# QEMU_RISCV_VIRT register map
Vendor: qemu.org; Series: RISC-V; File version: 0.1
QEMU RISC-V Virt Machine Platform
CPU: riscv r0p0, little endian, no MPU, no FPU, 0 interrupt priority bits
Registers are 32-bit, read-write, reset 0x0 unless marked. A register's access mark holds for its fields unless they carry their own. Offsets are from the block's base; lines under a group give offsets from that group; [hi:lo] are bit positions; {n}, {i} and the like mark numbered series; 'fields as' and 'values as' point back to an identical list; <NAME> marks a mode.

## Memory map
0x02000000 CLINT size 0x10000 — Core Local Interruptor (SiFive CLINT compatible)
0x0C000000 PLIC size 0x201000 — Platform-Level Interrupt Controller (SiFive PLIC compatible)
0x10000000 UART0 size 0x1000 — NS16550A compatible UART
0x10001000 I2C0 size 0x1000 — ODP socket-backed I2C controller
0x10002000 I2C_TARGET size 0x1000 — ODP socket-backed I2C target
0x10003000 GPIO size 0x1000 — ODP socket-backed bidirectional GPIO controller (32 pins, one bit per pin)

## Interrupts
1 UART0 — UART0 interrupt (PLIC source 1)
2 I2C0 — I2C0 controller interrupt (PLIC source 2)
3 I2C_TARGET — I2C target interrupt (PLIC source 3)
4 GPIO — GPIO shared interrupt (PLIC source 4)

## CLINT — Core Local Interruptor (SiFive CLINT compatible)
Base 0x02000000
0x00 MSIP — Machine Software Interrupt Pending for hart 0
  [0] MSIP — Machine software interrupt pending
0x4000 MTIMECMP_LO — Machine timer compare low word for hart 0
0x4004 MTIMECMP_HI — Machine timer compare high word for hart 0
0xBFF8 MTIME_LO — Machine timer low word
0xBFFC MTIME_HI — Machine timer high word

## PLIC — Platform-Level Interrupt Controller (SiFive PLIC compatible)
Base 0x0C000000
{0x0+4i} PRIORITY[{i}] (i=0..31) — Priority for interrupt source {i} (source 0 is reserved)
  [2:0] PRIORITY — Priority level (0=disabled, 1=lowest, 7=highest)
{0x1000+4i} PENDING{i} (i=0..0) ro — Interrupt pending bits
{0x2000+4i} M_ENABLE{i} (i=0..0) — M-mode interrupt enable bits (context 0)
0x200000 M_THRESHOLD — M-mode priority threshold (context 0)
  [2:0] THRESHOLD — Priority threshold (interrupts with priority <= threshold are masked)
0x200004 M_CLAIM — M-mode interrupt claim/complete (context 0). Read to claim, write to complete.

## UART0 — NS16550A compatible UART
Base 0x10000000
0x00 DATA group — UART registers when DLAB=0
  0x00 RBR 8-bit ro — Receiver Buffer Register (DLAB=0)
  0x00 THR 8-bit wo — Transmitter Holding Register (DLAB=0)
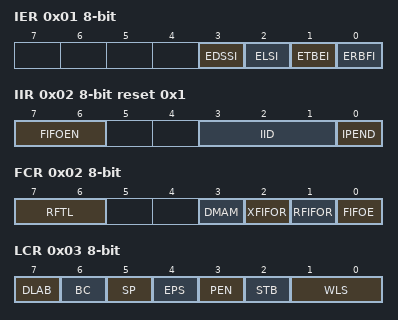
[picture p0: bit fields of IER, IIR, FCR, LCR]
  0x01 IER 8-bit — Interrupt Enable Register (DLAB=0)
    [3] EDSSI — Enable Modem Status Interrupt
    [2] ELSI — Enable Receiver Line Status Interrupt
    [1] ETBEI — Enable Transmitter Holding Register Empty Interrupt
    [0] ERBFI — Enable Received Data Available Interrupt
  0x02 IIR 8-bit ro reset 0x1 — Interrupt Identification Register
    [7:6] FIFOEN — FIFOs enabled
    [3:1] IID — Interrupt ID
    [0] IPEND — Interrupt NOT pending (0 = interrupt pending)
  0x02 FCR 8-bit wo — FIFO Control Register
    [7:6] RFTL — Receiver FIFO trigger level
    [3] DMAM — DMA mode select
    [2] XFIFOR — Transmitter FIFO reset (self-clearing)
    [1] RFIFOR — Receiver FIFO reset (self-clearing)
    [0] FIFOE — FIFO enable
  0x03 LCR 8-bit — Line Control Register
    [7] DLAB — Divisor latch access bit
    [6] BC — Break control
    [5] SP — Stick parity
    [4] EPS — Even parity select
    [3] PEN — Parity enable
    [2] STB — Number of stop bits
    [1:0] WLS — Word length select
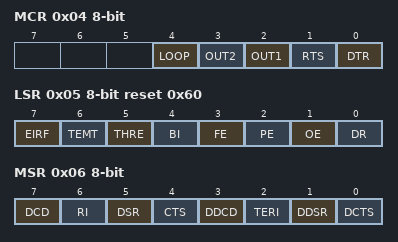
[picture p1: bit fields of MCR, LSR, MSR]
  0x04 MCR 8-bit — Modem Control Register
    [4] LOOP — Loopback mode
    [3] OUT2 — Output 2
    [2] OUT1 — Output 1
    [1] RTS — Request to send
    [0] DTR — Data terminal ready
  0x05 LSR 8-bit ro reset 0x60 — Line Status Register
    [7] EIRF — Error in receiver FIFO
    [6] TEMT — Transmitter empty
    [5] THRE — Transmitter holding register empty
    [4] BI — Break interrupt
    [3] FE — Framing error
    [2] PE — Parity error
    [1] OE — Overrun error
    [0] DR — Data ready
  0x06 MSR 8-bit ro — Modem Status Register
    [7] DCD — Data carrier detect
    [6] RI — Ring indicator
    [5] DSR — Data set ready
    [4] CTS — Clear to send
    [3] DDCD — Delta data carrier detect
    [2] TERI — Trailing edge ring indicator
    [1] DDSR — Delta data set ready
    [0] DCTS — Delta clear to send
  0x07 SCR 8-bit — Scratch Register
0x00 DLAB group (alternate view of DATA) — UART registers when DLAB=1
  0x00 DLL 8-bit — Divisor Latch LSB (DLAB=1)
  0x01 DLM 8-bit — Divisor Latch MSB (DLAB=1)
  0x02 IIR 8-bit ro reset 0x1 — Interrupt Identification Register
    fields as DATA.IIR
  0x02 FCR 8-bit wo — FIFO Control Register
    fields as DATA.FCR
  0x03 LCR 8-bit — Line Control Register
    fields as DATA.LCR
  0x04 MCR 8-bit — Modem Control Register
    fields as DATA.MCR
  0x05 LSR 8-bit ro reset 0x60 — Line Status Register
    fields as DATA.LSR
  0x06 MSR 8-bit ro — Modem Status Register
    fields as DATA.MSR
  0x07 SCR 8-bit — Scratch Register

## I2C0 — ODP socket-backed I2C controller
Base 0x10001000
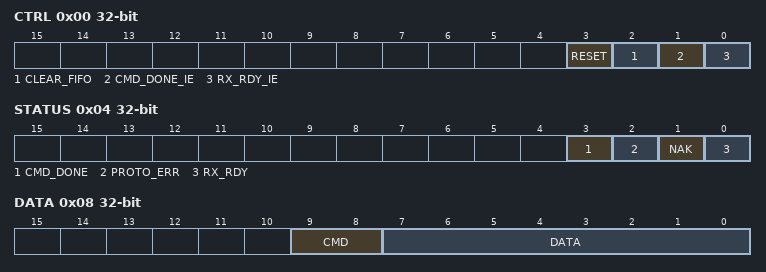
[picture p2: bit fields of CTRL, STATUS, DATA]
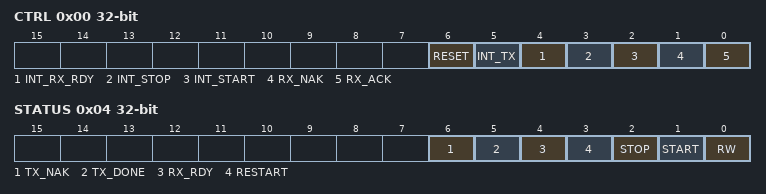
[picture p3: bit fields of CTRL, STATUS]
0x00 CTRL — Control register
  [3] RESET write-1-sets — Soft reset (write-1, self-clearing)
  [2] CLEAR_FIFO write-1-clears — Clear RX FIFO (write-1, self-clearing)
  [1] CMD_DONE_IE — Command-complete interrupt enable
  [0] RX_RDY_IE — RX-ready interrupt enable
0x04 STATUS
  [3] CMD_DONE write-1-clears — Command completed (write-1-to-clear)
  [2] PROTO_ERR write-1-clears — Illegal command ordering (write-1-to-clear)
  [1] NAK write-1-clears — Target NAKed / link dropped (write-1-to-clear)
  [0] RX_RDY ro — RX FIFO not empty
0x08 DATA — Data register: read pops RX FIFO; write issues a command
  [9:8] CMD — Command on write (0=START, 1=STOP, 2=RX, 3=TX)
  [7:0] DATA — Data byte (RX byte on read, TX/address byte on write)

## I2C_TARGET — ODP socket-backed I2C target
Base 0x10002000
0x00 CTRL — Control register
  [6] RESET write-1-sets — Recover / soft reset (write-1, self-clearing)
  [5] INT_TX — Interrupt enable: TX done
  [4] INT_RX_RDY — Interrupt enable: byte received
  [3] INT_STOP — Interrupt enable: STOP
  [2] INT_START — Interrupt enable: addressed (START)
  [1] RX_NAK write-1-sets — NAK pending RX byte / reject (write-1 strobe)
  [0] RX_ACK write-1-sets — ACK pending RX byte and continue (write-1 strobe)
0x04 STATUS
  [6] TX_NAK ro — Last TX byte: 1=controller NAKed (done)
  [5] TX_DONE write-1-clears — TX byte clocked and controller replied (write-1-to-clear)
  [4] RX_RDY ro — Byte in DATA awaiting strobe
  [3] RESTART write-1-clears — Repeated START, also sets START (write-1-to-clear)
  [2] STOP write-1-clears — Controller sent STOP (write-1-to-clear)
  [1] START write-1-clears — Addressed: address matched (write-1-to-clear)
  [0] RW ro — Transfer direction (1=controller read, 0=controller write)
0x08 ADDR — Target match address
  [6:0] ADDR — 7-bit address this target answers to
0x0C DATA — Data register: RX byte on read, TX byte on write
  [7:0] DATA — Data byte

## GPIO — ODP socket-backed bidirectional GPIO controller (32 pins, one bit per pin)
Base 0x10003000
0x00 IN ro — Input level (one bit per pin, driven by each pin's peer)
  [31:0] IN — Per-pin input level
0x04 OUT — Output level (one bit per pin, driven to each pin's peer)
  [31:0] OUT — Per-pin output level
0x08 IRQ_TRIG — Interrupt trigger type (0 = level, 1 = edge)
  [31:0] IRQ_TRIG — Per-pin trigger select (0 = level, 1 = edge)
0x0C IRQ_POL — Interrupt polarity (0 = low/falling, 1 = high/rising)
  [31:0] IRQ_POL — Per-pin polarity select (0 = low/falling, 1 = high/rising)
0x10 IRQ_EN — Per-pin interrupt enable
0x14 IRQ_PEND — Per-pin interrupt pending (write-1-to-clear)
  [31:0] IRQ_PEND write-1-clears
0x18 INPUT_INITIALIZED ro — Initialized external input mask (one bit per pin)
  [31:0] INPUT_INITIALIZED — Input level has been explicitly initialized
